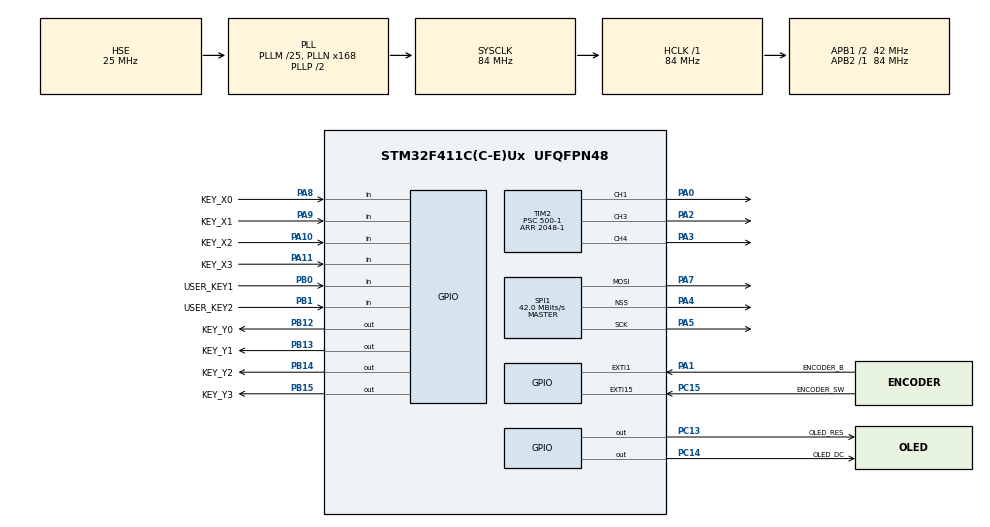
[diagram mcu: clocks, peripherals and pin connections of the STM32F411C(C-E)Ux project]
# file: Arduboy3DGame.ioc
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Mcu.Family=STM32F4
Mcu.Name=STM32F411C(C-E)Ux
Mcu.Package=UFQFPN48
NVIC.PriorityGroup=NVIC_PRIORITYGROUP_4
NVIC.TIM2_IRQn=true\:0\:0\:false\:false\:true\:true\:true\:true
PA0-WKUP.Signal=S_TIM2_CH1_ETR
PA1.GPIO_Label=ENCODER_B
PA1.Signal=GPXTI1
PA10.GPIO_Label=KEY_X2
PA10.GPIO_PuPd=GPIO_PULLUP
PA10.Signal=GPIO_Input
PA11.GPIO_Label=KEY_X3
PA11.GPIO_PuPd=GPIO_PULLUP
PA11.Signal=GPIO_Input
PA13.Mode=Serial_Wire
PA13.Signal=SYS_JTMS-SWDIO
PA14.Mode=Serial_Wire
PA14.Signal=SYS_JTCK-SWCLK
PA2.Signal=S_TIM2_CH3
PA3.Signal=S_TIM2_CH4
PA4.Mode=NSS_Signal_Hard_Output
PA4.Signal=SPI1_NSS
PA5.Mode=TX_Only_Simplex_Unidirect_Master
PA5.Signal=SPI1_SCK
PA7.Mode=TX_Only_Simplex_Unidirect_Master
PA7.Signal=SPI1_MOSI
PA8.GPIO_Label=KEY_X0
PA8.GPIO_PuPd=GPIO_PULLUP
PA8.Signal=GPIO_Input
PA9.GPIO_Label=KEY_X1
PA9.GPIO_PuPd=GPIO_PULLUP
PA9.Signal=GPIO_Input
PB0.GPIO_Label=USER_KEY1
PB0.GPIO_PuPd=GPIO_PULLUP
PB0.Signal=GPIO_Input
PB1.GPIO_Label=USER_KEY2
PB1.GPIO_PuPd=GPIO_PULLUP
PB1.Signal=GPIO_Input
PB12.GPIO_Label=KEY_Y0
PB12.Signal=GPIO_Output
PB13.GPIO_Label=KEY_Y1
PB13.Signal=GPIO_Output
PB14.GPIO_Label=KEY_Y2
PB14.Signal=GPIO_Output
PB15.GPIO_Label=KEY_Y3
PB15.Signal=GPIO_Output
PC13-ANTI_TAMP.GPIO_Label=OLED_RES
PC13-ANTI_TAMP.Signal=GPIO_Output
PC14-OSC32_IN.GPIO_Label=OLED_DC
PC14-OSC32_IN.Signal=GPIO_Output
PC15-OSC32_OUT.GPIO_Label=ENCODER_SW
PC15-OSC32_OUT.Signal=GPXTI15
PH0\ -\ OSC_IN.Mode=HSE-External-Oscillator
PH0\ -\ OSC_IN.Signal=RCC_OSC_IN
PH1\ -\ OSC_OUT.Mode=HSE-External-Oscillator
PH1\ -\ OSC_OUT.Signal=RCC_OSC_OUT
ProjectManager.HeapSize=0x200
ProjectManager.StackSize=0x400
ProjectManager.TargetToolchain=CMake
RCC.48MHZClocksFreq_Value=42000000
RCC.AHBFreq_Value=84000000
RCC.APB1CLKDivider=RCC_HCLK_DIV2
RCC.APB1Freq_Value=42000000
RCC.APB1TimFreq_Value=84000000
RCC.APB2Freq_Value=84000000
RCC.APB2TimFreq_Value=84000000
RCC.CortexFreq_Value=84000000
RCC.HCLKFreq_Value=84000000
RCC.HSE_VALUE=25000000
RCC.HSI_VALUE=16000000
RCC.LSE_VALUE=32768
RCC.PLLM=25
RCC.PLLN=168
RCC.PLLSourceVirtual=RCC_PLLSOURCE_HSE
RCC.SYSCLKFreq_VALUE=84000000
RCC.SYSCLKSource=RCC_SYSCLKSOURCE_PLLCLK
RCC.VCOOutputFreq_Value=168000000
SH.S_TIM2_CH1_ETR.0=TIM2_CH1,PWM Generation1 CH1
SH.S_TIM2_CH3.0=TIM2_CH3,PWM Generation3 CH3
SH.S_TIM2_CH4.0=TIM2_CH4,PWM Generation4 CH4
SPI1.CalculateBaudRate=42.0 MBits/s
SPI1.Direction=SPI_DIRECTION_2LINES
SPI1.Mode=SPI_MODE_MASTER
SPI1.VirtualNSS=VM_NSSHARD
SPI1.VirtualType=VM_MASTER
TIM1.Period=100-1
TIM1.Prescaler=84-1
TIM2.Channel-PWM\ Generation1\ CH1=TIM_CHANNEL_1
TIM2.Channel-PWM\ Generation3\ CH3=TIM_CHANNEL_3
TIM2.Channel-PWM\ Generation4\ CH4=TIM_CHANNEL_4
TIM2.Period=2048-1
TIM2.Prescaler=500-1
VP_TIM1_VS_ClockSourceINT.Mode=Internal
VP_TIM2_VS_ClockSourceINT.Mode=Internal
board=custom

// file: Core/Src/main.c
/* USER CODE BEGIN Header */
/**
  ******************************************************************************
  * @file           : main.c
  * @brief          : Main program body
  ******************************************************************************
  * @attention
  *
  * Copyright (c) 2025 STMicroelectronics.
  * All rights reserved.
  *
  * This software is licensed under terms that can be found in the LICENSE file
  * in the root directory of this software component.
  * If no LICENSE file comes with this software, it is provided AS-IS.
  *
  ******************************************************************************
  */
/* USER CODE END Header */
#include "main.h"
#include "Game_CApi.h"
#include "oled.h"
#include "spi.h"
#include "stm32f4xx_hal.h"
#include "tim.h"
#include "gpio.h"

/* USER CODE BEGIN Includes */
#include "u8g2.h"
#include "matrixkey.h"
#include <stdint.h>
#include <stdlib.h>
#include "Game_CAPI.h"
/* USER CODE END Includes */

/* USER CODE BEGIN PV */
extern u8g2_t screen;
/* USER CODE END PV */

void SystemClock_Config(void);

int main(void)
{

  /* MCU Configuration--------------------------------------------------------*/

  /* Reset of all peripherals, Initializes the Flash interface and the Systick. */
  HAL_Init();

  /* Configure the system clock */
  SystemClock_Config();

  /* Initialize all configured peripherals */
  MX_GPIO_Init();
  MX_SPI1_Init();
  MX_TIM1_Init();
  MX_TIM2_Init();
  /* USER CODE BEGIN 2 */
  oled_init();
  Game_Init();
  /* USER CODE END 2 */

  /* Infinite loop */
  /* USER CODE BEGIN WHILE */
  while (1)
  {
    Game_Tick();
    Game_Draw();
    u8g2_SendBuffer(&screen);
    /* USER CODE END WHILE */

  }
}

void SystemClock_Config(void)
{
  RCC_OscInitTypeDef RCC_OscInitStruct = {0};
  RCC_ClkInitTypeDef RCC_ClkInitStruct = {0};

  /** Configure the main internal regulator output voltage
  */
  __HAL_RCC_PWR_CLK_ENABLE();
  __HAL_PWR_VOLTAGESCALING_CONFIG(PWR_REGULATOR_VOLTAGE_SCALE1);

  /** Initializes the RCC Oscillators according to the specified parameters
  * in the RCC_OscInitTypeDef structure.
  */
  RCC_OscInitStruct.OscillatorType = RCC_OSCILLATORTYPE_HSE;
  RCC_OscInitStruct.HSEState = RCC_HSE_ON;
  RCC_OscInitStruct.PLL.PLLState = RCC_PLL_ON;
  RCC_OscInitStruct.PLL.PLLSource = RCC_PLLSOURCE_HSE;
  RCC_OscInitStruct.PLL.PLLM = 25;
  RCC_OscInitStruct.PLL.PLLN = 168;
  RCC_OscInitStruct.PLL.PLLP = RCC_PLLP_DIV2;
  RCC_OscInitStruct.PLL.PLLQ = 4;
  if (HAL_RCC_OscConfig(&RCC_OscInitStruct) != HAL_OK)
  {
    Error_Handler();
  }

  /** Initializes the CPU, AHB and APB buses clocks
  */
  RCC_ClkInitStruct.ClockType = RCC_CLOCKTYPE_HCLK|RCC_CLOCKTYPE_SYSCLK
                              |RCC_CLOCKTYPE_PCLK1|RCC_CLOCKTYPE_PCLK2;
  RCC_ClkInitStruct.SYSCLKSource = RCC_SYSCLKSOURCE_PLLCLK;
  RCC_ClkInitStruct.AHBCLKDivider = RCC_SYSCLK_DIV1;
  RCC_ClkInitStruct.APB1CLKDivider = RCC_HCLK_DIV2;
  RCC_ClkInitStruct.APB2CLKDivider = RCC_HCLK_DIV1;

  if (HAL_RCC_ClockConfig(&RCC_ClkInitStruct, FLASH_LATENCY_2) != HAL_OK)
  {
    Error_Handler();
  }
}

void Error_Handler(void)
{
  __disable_irq();
  while (1)
  {
  }
}
